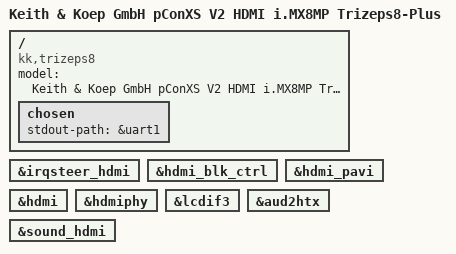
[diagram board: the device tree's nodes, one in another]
/*
 * Copyright 2022 Keith & Koep GmbH
 *
 */

/dts-v1/;

// Add defines here, which control behaviour of .dtsi:

#include "trizeps8plus.dtsi"
#include "hdmi-tr8p.dtsi"

/ {
	model      = "Keith & Koep GmbH pConXS V2 HDMI i.MX8MP Trizeps8-Plus";
	compatible = "kk,trizeps8", "kk,trizeps8mini", "kk,trizeps8plus", "fsl,imx8mp-evk", "fsl,imx8mp";

	chosen {
		stdout-path = &uart1;
	};
};

&irqsteer_hdmi {
	status = "okay";
};

&hdmi_blk_ctrl {
	status = "okay";
};

&hdmi_pavi {
	status = "okay";
};

&hdmi {
	status = "okay";
};

&hdmiphy {
	status = "okay";
};

&lcdif3 {
	status = "okay";
};

// HDMI Audio
&aud2htx {
	status = "okay";
};

&sound_hdmi {
	status = "okay";
};
